# cpsw_ss register map
Vendor: Texas Instruments
Peripheral module from a debugger description file (folder am335x).
Registers are 32-bit, read-write, no defined reset value unless marked. A register's access mark holds for its fields unless they carry their own. Offsets are as the file gives them; lines under a group give offsets from that group; [hi:lo] are bit positions; {n}, {i} and the like mark numbered series; 'fields as' and 'values as' point back to an identical list; <NAME> marks a mode.

## cpsw_ss
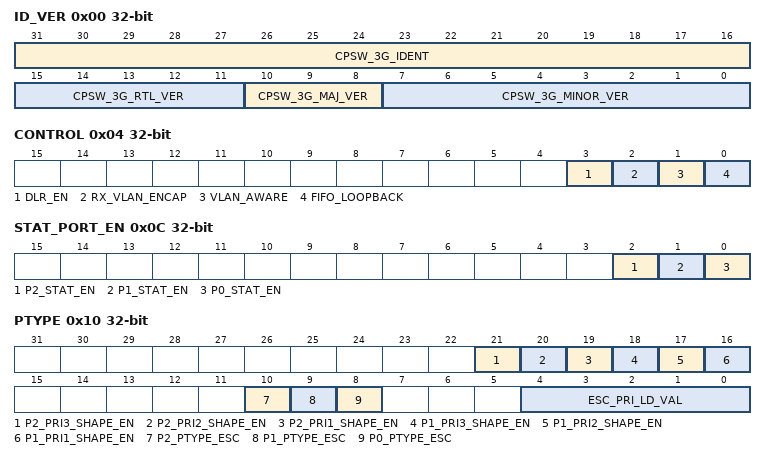
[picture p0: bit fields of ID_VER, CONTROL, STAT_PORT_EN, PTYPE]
0x00 ID_VER ro — ID VERSION REGISTER
  [31:16] CPSW_3G_IDENT — 3G Identification Value
  [15:11] CPSW_3G_RTL_VER — 3G RTL Version Value
  [10:8] CPSW_3G_MAJ_VER — 3G Major Version Value
  [7:0] CPSW_3G_MINOR_VER — 3G Minor Version Value
0x04 CONTROL — SWITCH CONTROL REGISTER
  [3] DLR_EN — DLR enable 0 - DLR is disabled. DLR packets will not be moved to queue priority 3 and will not be separated out onto dlr_cpdma_ch. 1 - DLR is disabled. DLR packets be moved to destination port transmit queue priority 3 and will be separated out onto dlr_cpdma_ch when packet is to egress on port 0.
  [2] RX_VLAN_ENCAP — Port 0 VLAN Encapsulation (egress): 0 - Port 2 receive packets (from 3G) are not VLAN encapsulated. 1 - Port 2 receive packets (from 3G) are VLAN encapsulated.
  [1] VLAN_AWARE — VLAN Aware Mode: 0 - 3G is in the VLAN unaware mode. 1 - 3G is in the VLAN aware mode.
  [0] FIFO_LOOPBACK — FIFO Loopback Mode 0 - Loopback is disabled 1 - FIFO Loopback mode enabled. Each packet received is turned around and sent out on the same port's transmit path. Port 2 receive is fixed on channel zero. The RXSOFOVERRUN statistic will increment for every packet sent in FIFO loopback mode.
0x08 SOFT_RESET
  [0] SOFT_RESET — Software reset - Writing a one to this bit causes the 3G logic to be reset. After writing a one to this bit, it may be polled to determine if the reset has occurred. If a one is read, the reset has not yet occurred. If a zero is read then reset has occurred.
0x0C STAT_PORT_EN — STATISTICS PORT ENABLE REGISTER
  [2] P2_STAT_EN — Port 2 (GMII2 and Port 2 FIFO) Statistics Enable 0 - Port 2 statistics are not enabled. 1 - Port 2 statistics are enabled.
  [1] P1_STAT_EN — Port 1 (GMII1 and Port 1 FIFO) Statistics Enable 0 - Port 1 statistics are not enabled. 1 - Port 1 statistics are enabled.
  [0] P0_STAT_EN — Port 0 Statistics Enable 0 - Port 0 statistics are not enabled 1 - Port 0 statistics are enabled. FIFO overruns (SOFOVERRUNS) are the only port 0 statistics that are enabled to be kept.
0x10 PTYPE — TRANSMIT PRIORITY TYPE REGISTER
  [21] P2_PRI3_SHAPE_EN — Port 2 Queue Priority 3 Transmit Shape Enable - If there is only one shaping queue then it must be priority 3.
  [20] P2_PRI2_SHAPE_EN — Port 2 Queue Priority 2 Transmit Shape Enable - If there are two shaping queues then they must be priorities 3 and 2.
  [19] P2_PRI1_SHAPE_EN — Port 2 Queue Priority 1 Transmit Shape Enable - If there are three shaping queues all three bits should be set.
  [18] P1_PRI3_SHAPE_EN — Port 1 Queue Priority 3 Transmit Shape Enable - If there is only one shaping queue then it must be priority 3.
  [17] P1_PRI2_SHAPE_EN — Port 1 Queue Priority 2 Transmit Shape Enable- If there are two shaping queues then they must be priorities 3 and 2.
  [16] P1_PRI1_SHAPE_EN — Port 1 Queue Priority 1 Transmit Shape Enable- If there are three shaping queues all three bits should be set.
  [10] P2_PTYPE_ESC — Port 2 Priority Type Escalate - 0 - Port 2 priority type fixed 1 - Port 2 priority type escalate Escalate should not be used with queue shaping.
  [9] P1_PTYPE_ESC — Port 1 Priority Type Escalate - 0 - Port 1 priority type fixed 1 - Port 1 priority type escalate Escalate should not be used with queue shaping.
  [8] P0_PTYPE_ESC — Port 0 Priority Type Escalate - 0 - Port 0 priority type fixed 1 - Port 0 priority type escalate Escalate should not be used with queue shaping.
  [4:0] ESC_PRI_LD_VAL — Escalate Priority Load Value When a port is in escalate priority, this is the number of higher priority packets sent before the next lower priority is allowed to send a packet. Escalate priority allows lower priority packets to be sent at a fixed rate relative to the next higher priority.
0x14 SOFT_IDLE — SOFTWARE IDLE
  [0] SOFT_IDLE — Software Idle - Setting this bit causes the switch fabric to stop forwarding packets at the next start of packet.
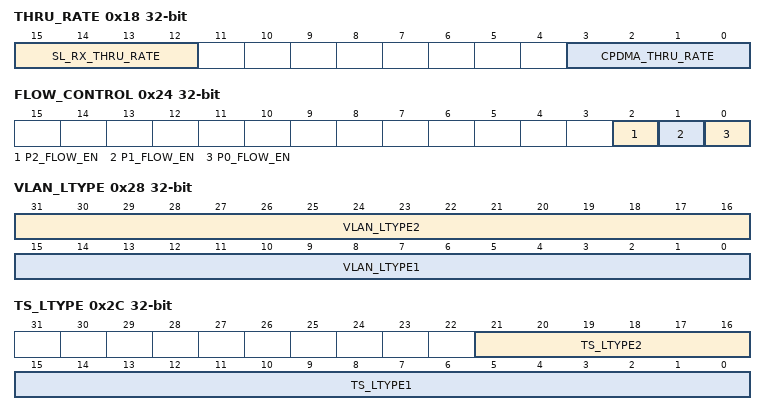
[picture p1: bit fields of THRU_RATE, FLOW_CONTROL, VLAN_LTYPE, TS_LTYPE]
0x18 THRU_RATE — THROUGHPUT RATE
  [15:12] SL_RX_THRU_RATE — CPGMAC_SL Switch FIFO receive through rate. This register value is the maximum throughput of the ethernet ports to the crossbar SCR. The default is one 8-byte word for every 3 CLK periods maximum.
  [3:0] CPDMA_THRU_RATE — CPDMA Switch FIFO receive through rate. This register value is the maximum throughput of the CPDMA host port to the crossbar SCR. The default is one 8-byte word for every 3 CLK periods maximum.
0x1C GAP_THRESH — CPGMAC_SL SHORT GAP THRESHOLD
  [4:0] GAP_THRESH — CPGMAC_SL Short Gap Threshold - This is the CPGMAC_SL associated FIFO transmit block usage value for triggering TX_SHORT_GAP.
0x20 TX_START_WDS — TRANSMIT START WORDS
  [10:0] TX_START_WDS — FIFO Packet Transmit (egress) Start Words. This value is the number of required packet words in the transmit FIFO before the packet egress will begin. This value is non-zero to preclude underrun. Decimal 32 is the recommended value. It should not be increased unnecessairly to prevent adding to the switch latency.
0x24 FLOW_CONTROL
  [2] P2_FLOW_EN — Port 2 Receive flow control enable
  [1] P1_FLOW_EN — Port 1 Receive flow control enable
  [0] P0_FLOW_EN — Port 0 Receive flow control enable
0x28 VLAN_LTYPE — LTYPE1 AND LTYPE 2 REGISTER
  [31:16] VLAN_LTYPE2 — Time Sync VLAN LTYPE2 This VLAN LTYPE value is used for tx and rx. This is the inner VLAN if both are present.
  [15:0] VLAN_LTYPE1 — Time Sync VLAN LTYPE1 This VLAN LTYPE value is used for tx and rx. This is the outer VLAN if both are present.
0x2C TS_LTYPE — VLAN_LTYPE1 AND VLAN_LTYPE2 REGISTER
  [21:16] TS_LTYPE2 — Time Sync LTYPE2 This is an Ethertype value to match for tx and rx time sync packets.
  [15:0] TS_LTYPE1 — Time Sync LTYPE1 This is an ethertype value to match for tx and rx time sync packets.
0x30 DLR_LTYPE
  [15:0] DLR_LTYPE
